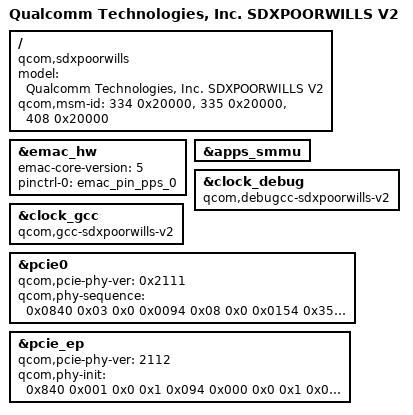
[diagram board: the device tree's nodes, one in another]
/* Copyright (c) 2018-2019, The Linux Foundation. All rights reserved.
 *
 * This program is free software; you can redistribute it and/or modify
 * it under the terms of the GNU General Public License version 2 and
 * only version 2 as published by the Free Software Foundation.
 *
 * This program is distributed in the hope that it will be useful,
 * but WITHOUT ANY WARRANTY; without even the implied warranty of
 * MERCHANTABILITY or FITNESS FOR A PARTICULAR PURPOSE.  See the
 * GNU General Public License for more details.
 */


/ {
	model = "Qualcomm Technologies, Inc. SDXPOORWILLS V2";
	compatible = "qcom,sdxpoorwills";
	qcom,msm-id = <334 0x20000>, <335 0x20000>, <408 0x20000>;
};

&emac_hw {
	emac-core-version = <5>;
	pinctrl-names = "dev-emac_pin_pps_0";
	pinctrl-0 = <&emac_pin_pps_0>;
};

&apps_smmu {
	/delete-property/ qcom,no-asid-retention;
};

&clock_debug {
	compatible = "qcom,debugcc-sdxpoorwills-v2", "syscon";
};

&clock_gcc {
	compatible = "qcom,gcc-sdxpoorwills-v2", "syscon";
};

&pcie0 {
	qcom,pcie-phy-ver = <0x2111>;

	qcom,phy-sequence = <0x0840 0x03 0x0
			0x0094 0x08 0x0
			0x0154 0x35 0x0
			0x0058 0x0f 0x0
			0x00a4 0x42 0x0
			0x0110 0x24 0x0
			0x01bc 0x11 0x0
			0x00bc 0x82 0x0
			0x00d4 0x03 0x0
			0x00d0 0x55 0x0
			0x00cc 0x55 0x0
			0x00b0 0x1a 0x0
			0x00ac 0x0a 0x0
			0x0158 0x01 0x0
			0x0074 0x06 0x0
			0x007c 0x16 0x0
			0x0084 0x36 0x0
			0x01b0 0x1e 0x0
			0x01ac 0xb9 0x0
			0x0010 0x00 0x0
			0x001c 0x31 0x0
			0x0020 0x01 0x0
			0x0024 0xde 0x0
			0x0028 0x07 0x0
			0x0050 0x07 0x0
			0x029c 0x12 0x0
			0x0284 0x05 0x0
			0x051c 0x03 0x0
			0x0518 0x1c 0x0
			0x0524 0x14 0x0
			0x04ec 0x0e 0x0
			0x04f0 0x4a 0x0
			0x04f4 0x0f 0x0
			0x05b4 0x04 0x0
			0x0434 0x7f 0x0
			0x0444 0x70 0x0
			0x0510 0x17 0x0
			0x04d8 0x01 0x0
			0x0598 0xd4 0x0
			0x059c 0x54 0x0
			0x05a0 0xdb 0x0
			0x05a4 0xb9 0x0
			0x05a8 0x31 0x0
			0x0584 0x24 0x0
			0x0588 0xe4 0x0
			0x058c 0xec 0x0
			0x0590 0xb9 0x0
			0x0594 0x36 0x0
			0x0570 0xef 0x0
			0x0574 0xef 0x0
			0x0578 0x2f 0x0
			0x057c 0xd3 0x0
			0x0580 0x40 0x0
			0x04fc 0x00 0x0
			0x04f8 0xc0 0x0
			0x0414 0x04 0x0
			0x09a4 0x01 0x0
			0x0c90 0x00 0x0
			0x0c40 0x01 0x0
			0x0c48 0x01 0x0
			0x0048 0x90 0x0
			0x0c1c 0xc1 0x0
			0x0988 0x66 0x0
			0x0998 0x08 0x0
			0x08dc 0x0d 0x0
			0x09ec 0x01 0x0
			0x0800 0x00 0x0
			0x0844 0x03 0x0>;
};

&pcie_ep {
	qcom,pcie-phy-ver = <2112>;

	qcom,phy-init = <0x840 0x001 0x0 0x1
			0x094 0x000 0x0 0x1
			0x058 0x00f 0x0 0x1
			0x0a4 0x042 0x0 0x1
			0x110 0x024 0x0 0x1
			0x1bc 0x011 0x0 0x1
			0x0bc 0x019 0x0 0x1
			0x0b0 0x004 0x0 0x1
			0x0ac 0x0ff 0x0 0x1
			0x158 0x001 0x0 0x1
			0x074 0x036 0x0 0x1
			0x07c 0x012 0x0 0x1
			0x084 0x000 0x0 0x1
			0x1b0 0x01d 0x0 0x1
			0x1ac 0x056 0x0 0x1
			0x04c 0x007 0x0 0x1
			0x050 0x007 0x0 0x1
			0x0f0 0x001 0x0 0x1
			0x0ec 0x0fb 0x0 0x1
			0x00c 0x002 0x0 0x1
			0x29c 0x012 0x0 0x1
			0x284 0x005 0x0 0x1
			0x51c 0x003 0x0 0x1
			0x518 0x01c 0x0 0x1
			0x524 0x014 0x0 0x1
			0x4ec 0x00e 0x0 0x1
			0x4f0 0x04a 0x0 0x1
			0x4f4 0x00f 0x0 0x1
			0x5b4 0x004 0x0 0x1
			0x434 0x07f 0x0 0x1
			0x444 0x070 0x0 0x1
			0x510 0x017 0x0 0x1
			0x4d8 0x001 0x0 0x1
			0x598 0x0d4 0x0 0x1
			0x59c 0x054 0x0 0x1
			0x5a0 0x0db 0x0 0x1
			0x5a4 0x0b9 0x0 0x1
			0x5a8 0x031 0x0 0x1
			0x584 0x024 0x0 0x1
			0x588 0x0e4 0x0 0x1
			0x58c 0x0ec 0x0 0x1
			0x590 0x0b9 0x0 0x1
			0x594 0x036 0x0 0x1
			0x570 0x0ef 0x0 0x1
			0x574 0x0ef 0x0 0x1
			0x578 0x02f 0x0 0x1
			0x57c 0x0d3 0x0 0x1
			0x580 0x040 0x0 0x1
			0x4fc 0x000 0x0 0x1
			0x4f8 0x0c0 0x0 0x1
			0x414 0x004 0x0 0x1
			0x9a4 0x001 0x0 0x1
			0xc40 0x001 0x0 0x1
			0xc48 0x001 0x0 0x1
			0x988 0x066 0x0 0x1
			0x998 0x008 0x0 0x1
			0x8dc 0x00d 0x0 0x1
			0x9ec 0x001 0x0 0x1
			0x800 0x000 0x0 0x1
			0x844 0x003 0x0 0x1>;
};
